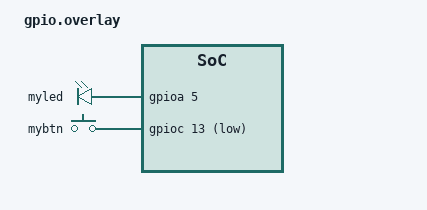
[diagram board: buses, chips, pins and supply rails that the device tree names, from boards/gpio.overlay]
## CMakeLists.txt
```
cmake_minimum_required(VERSION 3.20.0)
set(DTC_OVERLAY_FILE "boards/gpio.overlay")
find_package(Zephyr REQUIRED HINTS &ENV{ZEPHYR_BASE})
project(app_gpio)
target_sources(app PRIVATE src/main.c)
```

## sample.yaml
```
sample:
  name: GPIO Control Example
  description: GPIO example with LED control and button input with debouncing
tests:
  sample.app.gpio:
    tags:
      - gpio
      - LED
      - button
    filter: dt_enabled_alias_with_parent_compat("myled", "gpio-leds") and dt_enabled_alias_with_parent_compat("mybtn", "gpio-keys")
    depends_on: gpio
    harness: console
    harness_config:
      type: multi_line
      regex:
        - "mode has changed"
```

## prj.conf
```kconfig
CONFIG_GPIO=y
CONFIG_LOG=y 
```

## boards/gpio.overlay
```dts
/{
    aliases {
        myled = &myled;
		mybtn = &mybtn;
    };

    gpio_leds {
		compatible = "gpio-leds";
		myled: myled {
    		gpios = <&gpioa 5 GPIO_ACTIVE_HIGH>;
		};
	};

	gpio_btn{
		compatible = "gpio-keys";
		mybtn: mybtn{
			gpios = <&gpioc 13 GPIO_ACTIVE_LOW>;
		};
	};
};
```

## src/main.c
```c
#include <stdint.h>
#include <zephyr/kernel.h>
#include <zephyr/drivers/gpio.h>
#include <zephyr/logging/log.h>

#define LED_NODE          DT_ALIAS(myled)
#define BTN_NODE          DT_ALIAS(mybtn)

#define TIME_MS           1000

LOG_MODULE_REGISTER(app_gpio, CONFIG_LOG_MAX_LEVEL);

static const struct gpio_dt_spec myled0 = GPIO_DT_SPEC_GET(LED_NODE, gpios);   
static const struct gpio_dt_spec mybtn0 = GPIO_DT_SPEC_GET(BTN_NODE, gpios); 

int main()
{
	int8_t ret = 0; 
	uint8_t btn_state = 0; 
	uint8_t prev_btn_state = 0;
	uint8_t mode = 0;

	// TODO: OUTPUT CONFIGURATION
	ret = gpio_pin_configure_dt(&myled0, GPIO_OUTPUT_INACTIVE);
	if(ret < 0) LOG_ERR("LED configure as output failed");

	// TODO: INPUT CONFIGURATION 
	ret = gpio_pin_configure_dt(&mybtn0, GPIO_INPUT|GPIO_PULL_UP);
	if(ret < 0) LOG_ERR("Button configure as input failed");

	while(1)
	{
		//TODO: Debounce algorithm
		btn_state = gpio_pin_get_dt(&mybtn0);
		k_msleep(20);
		if(btn_state != prev_btn_state) {
		    k_msleep(20);
			btn_state = gpio_pin_get_dt(&mybtn0);		

		    if(btn_state != prev_btn_state)
		   {
		    	mode++;
				LOG_INF("mode has changed to %d", mode);
		   }	
		   
		   switch(mode)
		   {
			case 0: 
				gpio_pin_set_dt(&myled0, 0);
		   		LOG_INF("MODE %d: LED is off", mode);
				break;
			case 1:
				gpio_pin_set_dt(&myled0,1);
		   		LOG_INF("MODE %d: LED is on", mode);
				break;

		   }
		 }
							
		if(mode > 1) 
		{
			mode = 0;
			LOG_INF("Mode has reset to %d", mode);
		}
		
	}			
	return 0;
}
```
